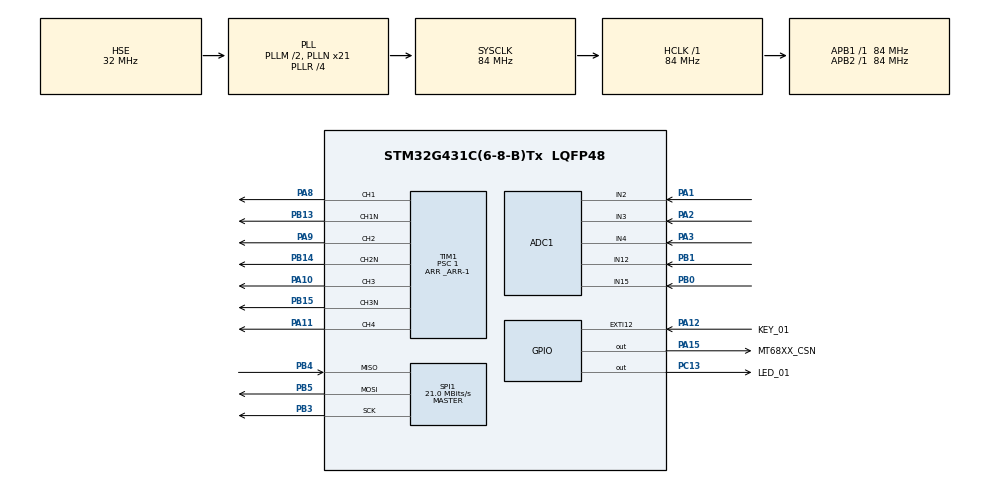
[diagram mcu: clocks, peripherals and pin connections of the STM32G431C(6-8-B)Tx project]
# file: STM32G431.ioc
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ADC1.Channel-8\#ChannelRegularConversion=ADC_CHANNEL_12
ADC1.Channel-9\#ChannelRegularConversion=ADC_CHANNEL_15
ADC1.ClockPrescaler=ADC_CLOCK_ASYNC_DIV4
ADC1.ContinuousConvMode=DISABLE
ADC1.EnableInjectedConversion=ENABLE
ADC1.ExternalTrigInjecConv=ADC_EXTERNALTRIGINJEC_T1_CC4
ADC1.ExternalTrigInjecConvEdge=ADC_EXTERNALTRIGINJECCONV_EDGE_FALLING
ADC1.InjNumberOfConversion=3
ADC1.InjectedChannel-10\#ChannelInjectedConversion=ADC_CHANNEL_2
ADC1.InjectedChannel-11\#ChannelInjectedConversion=ADC_CHANNEL_3
ADC1.InjectedChannel-12\#ChannelInjectedConversion=ADC_CHANNEL_4
ADC1.InjectedOffsetNumber-10\#ChannelInjectedConversion=ADC_OFFSET_NONE
ADC1.InjectedOffsetNumber-11\#ChannelInjectedConversion=ADC_OFFSET_NONE
ADC1.InjectedOffsetNumber-12\#ChannelInjectedConversion=ADC_OFFSET_NONE
ADC1.InjectedRank-10\#ChannelInjectedConversion=1
ADC1.InjectedRank-11\#ChannelInjectedConversion=2
ADC1.InjectedRank-12\#ChannelInjectedConversion=3
ADC1.InjectedSamplingTime-10\#ChannelInjectedConversion=ADC_SAMPLETIME_2CYCLES_5
ADC1.InjectedSamplingTime-11\#ChannelInjectedConversion=ADC_SAMPLETIME_2CYCLES_5
ADC1.InjectedSamplingTime-12\#ChannelInjectedConversion=ADC_SAMPLETIME_2CYCLES_5
ADC1.NbrOfConversion=2
ADC1.NbrOfConversionFlag=1
ADC1.OffsetNumber-8\#ChannelRegularConversion=ADC_OFFSET_NONE
ADC1.OffsetNumber-9\#ChannelRegularConversion=ADC_OFFSET_NONE
ADC1.Rank-8\#ChannelRegularConversion=1
ADC1.Rank-9\#ChannelRegularConversion=2
ADC1.SamplingTime-8\#ChannelRegularConversion=ADC_SAMPLETIME_2CYCLES_5
ADC1.SamplingTime-9\#ChannelRegularConversion=ADC_SAMPLETIME_2CYCLES_5
ADC1.master=1
Mcu.Family=STM32G4
Mcu.Name=STM32G431C(6-8-B)Tx
Mcu.Package=LQFP48
Mcu.UserConstants=_ARR,2100
NVIC.ADC1_2_IRQn=true\:0\:0\:false\:false\:true\:true\:true\:true
NVIC.EXTI15_10_IRQn=true\:3\:0\:true\:false\:true\:true\:true\:true
NVIC.PriorityGroup=NVIC_PRIORITYGROUP_4
PA1.Mode=IN2-Single-Ended
PA1.Signal=ADC1_IN2
PA10.Signal=S_TIM1_CH3
PA11.Signal=S_TIM1_CH4
PA12.GPIO_Label=KEY_01
PA12.Signal=GPXTI12
PA13.Mode=Serial_Wire
PA13.Signal=SYS_JTMS-SWDIO
PA14.Mode=Serial_Wire
PA14.Signal=SYS_JTCK-SWCLK
PA15.GPIO_Label=MT68XX_CSN
PA15.Signal=GPIO_Output
PA2.Mode=IN3-Single-Ended
PA2.Signal=ADC1_IN3
PA3.Mode=IN4-Single-Ended
PA3.Signal=ADC1_IN4
PA8.Signal=S_TIM1_CH1
PA9.Signal=S_TIM1_CH2
PB0.Mode=IN15-Single-Ended
PB0.Signal=ADC1_IN15
PB1.Mode=IN12-Single-Ended
PB1.Signal=ADC1_IN12
PB13.Mode=PWM Generation1 CH1 CH1N
PB13.Signal=TIM1_CH1N
PB14.Mode=PWM Generation2 CH2 CH2N
PB14.Signal=TIM1_CH2N
PB15.Mode=PWM Generation3 CH3 CH3N
PB15.Signal=TIM1_CH3N
PB3.Mode=Full_Duplex_Master
PB3.Signal=SPI1_SCK
PB4.Mode=Full_Duplex_Master
PB4.Signal=SPI1_MISO
PB5.Mode=Full_Duplex_Master
PB5.Signal=SPI1_MOSI
PC13.GPIO_Label=LED_01
PC13.Signal=GPIO_Output
PF0-OSC_IN.Mode=HSE-External-Oscillator
PF0-OSC_IN.Signal=RCC_OSC_IN
PF1-OSC_OUT.Mode=HSE-External-Oscillator
PF1-OSC_OUT.Signal=RCC_OSC_OUT
ProjectManager.HeapSize=0x200
ProjectManager.StackSize=0x400
ProjectManager.TargetToolchain=Makefile
RCC.ADC12Freq_Value=84000000
RCC.AHBFreq_Value=84000000
RCC.APB1Freq_Value=84000000
RCC.APB1TimFreq_Value=84000000
RCC.APB2Freq_Value=84000000
RCC.APB2TimFreq_Value=84000000
RCC.CortexFreq_Value=84000000
RCC.EXTERNAL_CLOCK_VALUE=12288000
RCC.HCLKFreq_Value=84000000
RCC.HSE_VALUE=32000000
RCC.HSI48_VALUE=48000000
RCC.HSI_VALUE=16000000
RCC.LSE_VALUE=32768
RCC.PLLM=RCC_PLLM_DIV2
RCC.PLLN=21
RCC.PLLR=RCC_PLLR_DIV4
RCC.PLLSourceVirtual=RCC_PLLSOURCE_HSE
RCC.SYSCLKFreq_VALUE=84000000
RCC.SYSCLKSource=RCC_SYSCLKSOURCE_PLLCLK
RCC.USBFreq_Value=168000000
RCC.VCOOutputFreq_Value=336000000
SH.S_TIM1_CH1.0=TIM1_CH1,PWM Generation1 CH1 CH1N
SH.S_TIM1_CH2.0=TIM1_CH2,PWM Generation2 CH2 CH2N
SH.S_TIM1_CH3.0=TIM1_CH3,PWM Generation3 CH3 CH3N
SH.S_TIM1_CH4.0=TIM1_CH4,PWM Generation4 CH4
SPI1.BaudRatePrescaler=SPI_BAUDRATEPRESCALER_4
SPI1.CLKPhase=SPI_PHASE_2EDGE
SPI1.CLKPolarity=SPI_POLARITY_HIGH
SPI1.CalculateBaudRate=21.0 MBits/s
SPI1.DataSize=SPI_DATASIZE_8BIT
SPI1.Direction=SPI_DIRECTION_2LINES
SPI1.Mode=SPI_MODE_MASTER
SPI1.VirtualType=VM_MASTER
TIM1.Channel-PWM\ Generation1\ CH1\ CH1N=TIM_CHANNEL_1
TIM1.Channel-PWM\ Generation2\ CH2\ CH2N=TIM_CHANNEL_2
TIM1.Channel-PWM\ Generation3\ CH3\ CH3N=TIM_CHANNEL_3
TIM1.Channel-PWM\ Generation4\ CH4=TIM_CHANNEL_4
TIM1.ClockDivision=TIM_CLOCKDIVISION_DIV2
TIM1.CounterMode=TIM_COUNTERMODE_CENTERALIGNED1
TIM1.DeadTime=0
TIM1.PeriodNoDither=_ARR-1
TIM1.Prescaler=1
TIM1.PulseNoDither_2=1599
TIM1.PulseNoDither_4=1200
VP_SYS_VS_DBSignals.Mode=DisableDeadBatterySignals
VP_TIM1_VS_ClockSourceINT.Mode=Internal
board=custom

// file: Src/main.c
/* USER CODE BEGIN Header */
/**
  ******************************************************************************
  * @file           : main.c
  * @brief          : Main program body
  ******************************************************************************
  * @attention
  *
  * 1、simulink模型为单电流环
  * 2、q轴电流设置0.6
  * 3、按键按下，电机会出现卡死情况，手动转动，可以引导电机转动起来
  * 4、电机给小负载，电机的iq电流相对平滑，能够稳定在参考值附近
  * 5、q轴的电流设置不能过大，如0.8会导致电机失控，0.6几乎没有力矩，需要调整！！！
  ******************************************************************************
  */
/* USER CODE END Header */
#include "main.h"
#include "adc.h"
#include "spi.h"
#include "tim.h"
#include "gpio.h"

/* USER CODE BEGIN Includes */
#include "motortctrl.h"
#include "ipc.h"
/* USER CODE END Includes */

/* USER CODE BEGIN PM */
extern ADC_HandleTypeDef hadc1;
/* USER CODE END PM */

/* USER CODE BEGIN PV */

void HAL_GPIO_EXTI_Callback(uint16_t GPIO_Pin)
{
    /*------------------*/
    IPC_SET_EVENT(gEventGroup,KEY01_SHORT_PRESS);
}

/* USER CODE END PV */

void SystemClock_Config(void);

int main(void)
{

  /* MCU Configuration--------------------------------------------------------*/

  /* Reset of all peripherals, Initializes the Flash interface and the Systick. */
  HAL_Init();

  /* Configure the system clock */
  SystemClock_Config();

  /* Initialize all configured peripherals */
  MX_GPIO_Init();
  MX_TIM1_Init();
  MX_ADC1_Init();
  MX_SPI1_Init();
  /* USER CODE BEGIN 2 */
  HAL_GPIO_WritePin(LED_01_GPIO_Port,LED_01_Pin,GPIO_PIN_SET);
  /* USER CODE END 2 */

  /* Infinite loop */
  /* USER CODE BEGIN WHILE */
  while (1)
  {
    motortctrl_process();
    /* USER CODE END WHILE */
  }
}

void SystemClock_Config(void)
{
  RCC_OscInitTypeDef RCC_OscInitStruct = {0};
  RCC_ClkInitTypeDef RCC_ClkInitStruct = {0};

  /** Configure the main internal regulator output voltage
  */
  HAL_PWREx_ControlVoltageScaling(PWR_REGULATOR_VOLTAGE_SCALE1);

  /** Initializes the RCC Oscillators according to the specified parameters
  * in the RCC_OscInitTypeDef structure.
  */
  RCC_OscInitStruct.OscillatorType = RCC_OSCILLATORTYPE_HSE;
  RCC_OscInitStruct.HSEState = RCC_HSE_ON;
  RCC_OscInitStruct.PLL.PLLState = RCC_PLL_ON;
  RCC_OscInitStruct.PLL.PLLSource = RCC_PLLSOURCE_HSE;
  RCC_OscInitStruct.PLL.PLLM = RCC_PLLM_DIV2;
  RCC_OscInitStruct.PLL.PLLN = 21;
  RCC_OscInitStruct.PLL.PLLP = RCC_PLLP_DIV2;
  RCC_OscInitStruct.PLL.PLLQ = RCC_PLLQ_DIV2;
  RCC_OscInitStruct.PLL.PLLR = RCC_PLLR_DIV4;
  if (HAL_RCC_OscConfig(&RCC_OscInitStruct) != HAL_OK)
  {
    Error_Handler();
  }

  /** Initializes the CPU, AHB and APB buses clocks
  */
  RCC_ClkInitStruct.ClockType = RCC_CLOCKTYPE_HCLK|RCC_CLOCKTYPE_SYSCLK
                              |RCC_CLOCKTYPE_PCLK1|RCC_CLOCKTYPE_PCLK2;
  RCC_ClkInitStruct.SYSCLKSource = RCC_SYSCLKSOURCE_PLLCLK;
  RCC_ClkInitStruct.AHBCLKDivider = RCC_SYSCLK_DIV1;
  RCC_ClkInitStruct.APB1CLKDivider = RCC_HCLK_DIV1;
  RCC_ClkInitStruct.APB2CLKDivider = RCC_HCLK_DIV1;

  if (HAL_RCC_ClockConfig(&RCC_ClkInitStruct, FLASH_LATENCY_2) != HAL_OK)
  {
    Error_Handler();
  }
}

void Error_Handler(void)
{
  __disable_irq();
  while (1)
  {
  }
}
